VERSION "1.0"

NS_ :

BS_:

BU_: RLM Third_Party_Device

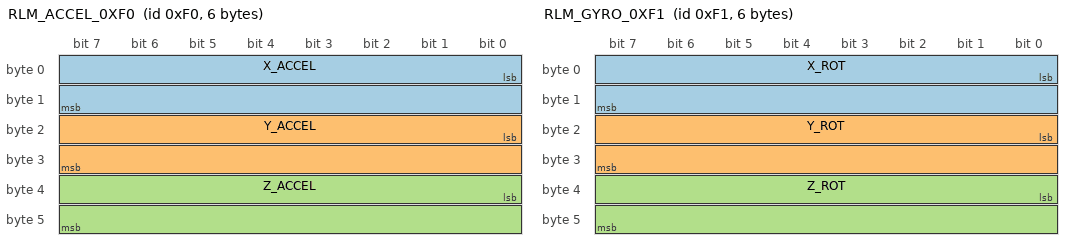
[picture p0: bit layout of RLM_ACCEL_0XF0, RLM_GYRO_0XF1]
BO_ 240 RLM_ACCEL_0XF0: 6 Vector__XXX
 SG_ X_ACCEL : 0|16@1- (0.000122,0) [-4|4] "g" Vector__XXX
 SG_ Y_ACCEL : 16|16@1- (0.000122,0) [-4|4] "g" Vector__XXX
 SG_ Z_ACCEL : 32|16@1- (0.000122,0) [-4|4] "g" Vector__XXX

BO_ 241 RLM_GYRO_0XF1: 6 Vector__XXX
 SG_ X_ROT : 0|16@1- (0.00763,0) [-250|250] "degree/s" Vector__XXX
 SG_ Y_ROT : 16|16@1- (0.00763,0) [-250|250] "degree/s" Vector__XXX
 SG_ Z_ROT : 32|16@1- (0.00763,0) [-250|250] "degree/s" Vector__XXX

BO_ 242 RLM_POSITION_0XF2: 8 Vector__XXX
 SG_ LATITUDE : 0|32@1- (0.0000001,0) [-90|90] "degree" Vector__XXX
 SG_ LONGITUDE : 32|32@1- (0.0000001,0) [-180|180] "degree" Vector__XXX

BO_ 243 RLM_TRAJECTORY_0XF3: 4 Vector__XXX
 SG_ SPEED : 0|16@1- (0.01,0) [0|0] "m/s" Vector__XXX
 SG_ DIRECTION : 16|16@1- (0.01,0) [0|360] "degree" Vector__XXX

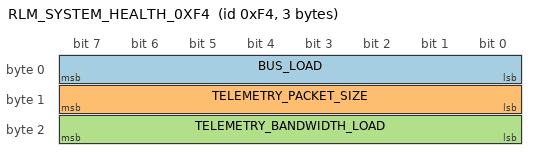
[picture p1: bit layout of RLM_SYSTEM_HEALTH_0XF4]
BO_ 244 RLM_SYSTEM_HEALTH_0XF4: 3 Vector__XXX
 SG_ BUS_LOAD : 0|8@1+ (0.5,0) [0|100] "%" Vector__XXX
 SG_ TELEMETRY_PACKET_SIZE : 8|8@1+ (0.25,0) [0|32] "bytes" Vector__XXX
 SG_ TELEMETRY_BANDWIDTH_LOAD : 16|8@1+ (0.5,0) [0|100] "%" Vector__XXX
